# G32M3101 register map
File version: 1.0
CPU: CM0+ r0p1, little endian, MPU, no FPU, 2 interrupt priority bits
Registers are 32-bit, read-write, reset 0x0 unless marked. A register's access mark holds for its fields unless they carry their own. Offsets are from the block's base; [hi:lo] are bit positions; lines under a group give offsets from that group; {n}, {i} and the like mark numbered series.

## LPTMR — Low-power timer
Base 0x4000A000
0x00 CTRL — Control register
  [0] EN — Module enablement
0x04 PSC — Prescaler register
  [15:0] PSC — Prescaler divider
0x08 WUPV reset 0xFFFF — Reload register
  [15:0] WUPV — Awakening Value
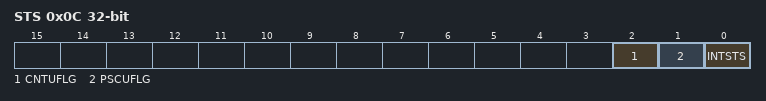
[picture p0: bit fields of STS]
0x0C STS access per field — Status register
  [2] CNTUFLG ro — Reload value update indication, automatically reset by hardware after update.
  [1] PSCUFLG ro — PS value update indicator, hardware automatically resets after update.
  [0] INTSTS rw — Status Register, read SR register clear.
0x10 CNT ro — Counter register
  [15:0] CNT — Counter Value

## SPI — Serial peripheral interface
Base 0x40003000
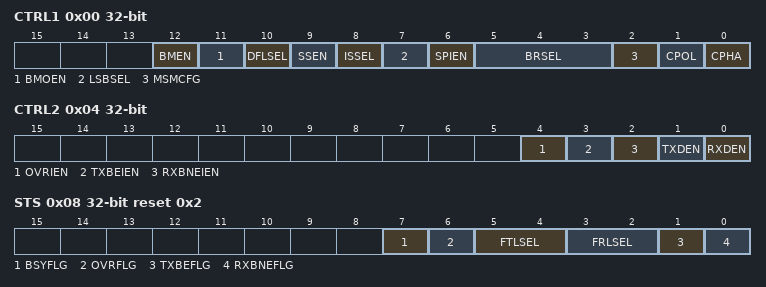
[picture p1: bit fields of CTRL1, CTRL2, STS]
0x00 CTRL1 — control register 1
  [12] BMEN — Bidirectional data mode enable
  [11] BMOEN — Output enable in bidirectional mode
  [10] DFLSEL — Receive only
  [9] SSEN — Software slave management
  [8] ISSEL — Internal slave select
  [7] LSBSEL — Frame format
  [6] SPIEN — SPI enable
  [5:3] BRSEL — Baud rate control
  [2] MSMCFG — Master selection
  [1] CPOL — Clock polarity
  [0] CPHA — Clock phase
0x04 CTRL2 — control register 2
  [4] OVRIEN — Overflow
  [3] TXBEIEN — Tx buffer empty interrupt enable
  [2] RXBNEIEN — SS output enable
  [1] TXDEN — Tx buffer DMA enable
  [0] RXDEN — Rx buffer DMA enable
0x08 STS ro reset 0x2 — status register
  [7] BSYFLG — Busy flag
  [6] OVRFLG — Overrun flag
  [5:4] FTLSEL — FTLVL
  [3:2] FRLSEL — FRLVL
  [1] TXBEFLG — Transmit buffer empty
  [0] RXBNEFLG — Receive buffer not empty
0x0C DATA
  [15:0] DATA

## UART0 — Universal asynchronous receiver transmitter
Base 0x40004000
Same registers: UART1 0x40005000
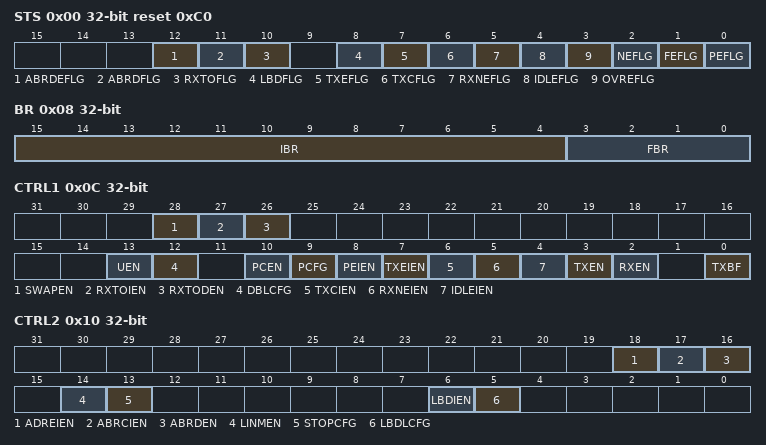
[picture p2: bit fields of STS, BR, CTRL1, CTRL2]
0x00 STS access per field reset 0xC0
  [12] ABRDEFLG rw — Auto Baud Rate Detection Error Flag
  [11] ABRDFLG rw — Auto Baud Rate Detection Flag
  [10] RXTOFLG rw — RX timeout flag
  [8] LBDFLG rw — LIN break detection flag
  [7] TXEFLG ro — Transmit data register empty
  [6] TXCFLG rw — Transmission complete
  [5] RXNEFLG rw — Read data register not empty
  [4] IDLEFLG ro — IDLE line detected
  [3] OVREFLG ro — Overrun error
  [2] NEFLG ro — Noise error flag
  [1] FEFLG ro — Framing error
  [0] PEFLG ro — Parity error
0x04 DATA
  [8:0] DATA — Data value
0x08 BR
  [15:4] IBR — IntegerwofwUARTwBaudwRatewDividerw factor
  [3:0] FBR — FractionwofwUARTwBaudwRatewDividerw factor
0x0C CTRL1
  [28] SWAPEN — Swap TX/RX Pins Function Enable
  [27] RXTOIEN — Receiver Timeout Interrupt Enable
  [26] RXTODEN — Receive Timeout Detection Function Enable
  [13] UEN — USART enable
  [12] DBLCFG — DatawBitswLengthwConfigure
  [10] PCEN — Parity control enable
  [9] PCFG — Parity selection
  [8] PEIEN — PE interrupt enable
  [7] TXEIEN — TXE interrupt enable
  [6] TXCIEN — Transmission complete interrupt enable
  [5] RXNEIEN — RXNE interrupt enable
  [4] IDLEIEN — IDLE interrupt enable
  [3] TXEN — Transmitter enable
  [2] RXEN — Receiver enable
  [0] TXBF — Send break
0x10 CTRL2
  [18] ADREIEN — Automaticwbaudwratewdetectionwerrorw interruptwenable
  [17] ABRCIEN — Automaticwbaudwratewcompletionwinterruptw enable
  [16] ABRDEN — AutowBaudwRatewDetectionwEnable
  [14] LINMEN — LIN mode enable
  [13] STOPCFG — STOP bits
  [6] LBDIEN — LIN break detection interrupt enable
  [5] LBDLCFG — LIN break detection length
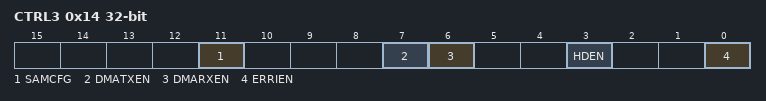
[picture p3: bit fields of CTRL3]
0x14 CTRL3
  [11] SAMCFG — Sample Method Configure
  [7] DMATXEN — DMA enable transmitter
  [6] DMARXEN — DMA enable receiver
  [3] HDEN — Half-duplex selection
  [0] ERRIEN — Error interrupt enable
0x1C RXTO
  [23:0] RXTO — Receiver Timeout Value Setup

## ADC — Analog-to-digital converter
Base 0x4000B000
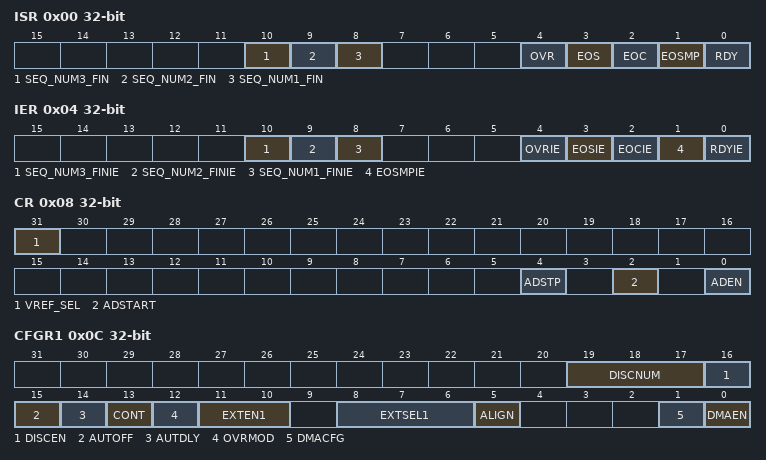
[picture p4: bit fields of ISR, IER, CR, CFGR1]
0x00 ISR — ADC interrupt and status register
  [10] SEQ_NUM3_FIN — NUM.3 of Sequential Section Sampling Finish
  [9] SEQ_NUM2_FIN — NUM.2 of Sequential Section Sampling Finish
  [8] SEQ_NUM1_FIN — NUM.1 of Sequential Section Sampling Finish
  [4] OVR — ADC group regular overrun flag
  [3] EOS — ADC group regular end of sequence conversions flag
  [2] EOC — ADC group regular end of unitary conversion flag
  [1] EOSMP — ADC group regular end of sampling flag
  [0] RDY — /
0x04 IER — ADC interrupt enable register
  [10] SEQ_NUM3_FINIE — NUM.3 of Sequential Section Sampling Finish interrupt
  [9] SEQ_NUM2_FINIE — NUM.2 of Sequential Section Sampling Finish interrupt
  [8] SEQ_NUM1_FINIE — NUM.1 of Sequential Section Sampling Finish interrupt
  [4] OVRIE — ADC group regular overrun interrupt
  [3] EOSIE — ADC group regular end of sequence conversions interrupt
  [2] EOCIE — ADC group regular end of unitary conversion interrupt
  [1] EOSMPIE — ADC group regular end of sampling interrupt
  [0] RDYIE — /
0x08 CR — ADC control register
  [31] VREF_SEL — ADC group injected conversion stop
  [4] ADSTP — ADC group regular conversion stop
  [2] ADSTART — ADC group regular conversion start
  [0] ADEN — ADC enable
0x0C CFGR1 — ADC configuration register 1
  [19:17] DISCNUM — ADC group regular sequencer discontinuous number of ranks
  [16] DISCEN — ADC group regular sequencer discontinuous mode
  [15] AUTOFF — ADC low power auto wait
  [14] AUTDLY — ADC low power auto wait
  [13] CONT — ADC group regular continuous conversion mode
  [12] OVRMOD — ADC group regular overrun configuration
  [11:10] EXTEN1 — ADC group regular external trigger polarity
  [8:6] EXTSEL1 — ADC group regular external trigger source
  [5] ALIGN — Data alignment
  [1] DMACFG — ADC DMA transfer configuration
  [0] DMAEN — ADC DMA transfer enable
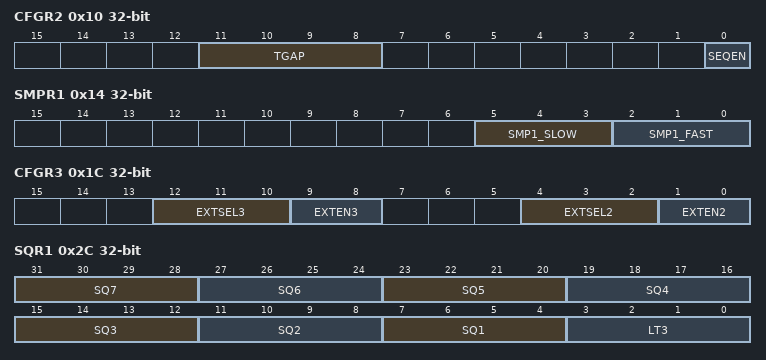
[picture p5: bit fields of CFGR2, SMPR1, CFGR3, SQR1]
0x10 CFGR2 — ADC configuration register 2
  [11:8] TGAP — Time of The Gap between Conversions in Sequential Section Configure
  [0] SEQEN — Sequential Section Sampling Enable
0x14 SMPR1 — ADC sampling time register 1
  [5:3] SMP1_SLOW — ADC channel 0 slow sampling time selection
  [2:0] SMP1_FAST — ADC channel 0 fast sampling time selection
0x1C CFGR3 — ADC configuration register 3
  [12:10] EXTSEL3 — External trigger selection for regular group
  [9:8] EXTEN3 — External trigger enable and polarity selection for regular channels
  [4:2] EXTSEL2 — External trigger selection for regular group
  [1:0] EXTEN2 — External trigger enable and polarity selection for regular channels
0x2C SQR1 — ADC group regular sequencer register 1
  [4n+3:4n] SQ{n} (n=1..7) — ADC group regular sequencer rank {n}
  [3:0] LT3 — ADC group regular sequencer scan length
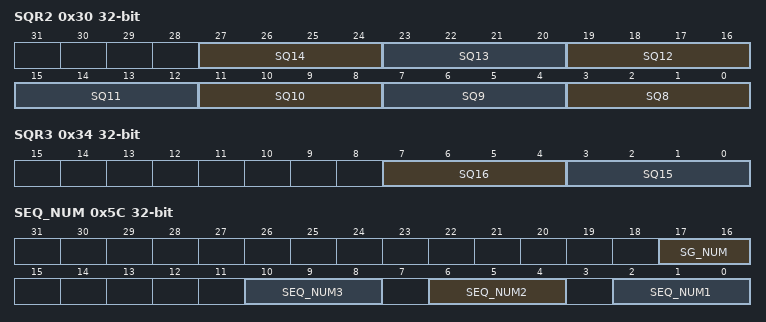
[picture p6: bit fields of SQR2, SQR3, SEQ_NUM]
0x30 SQR2 — ADC group regular sequencer register 2
  [4n-29:4n-32] SQ{n} (n=8..14) — ADC group regular sequencer rank {n}
0x34 SQR3 — ADC group regular sequencer register 3
  [7:4] SQ16 — ADC group regular sequencer rank 16
  [3:0] SQ15 — ADC group regular sequencer rank 15
0x38 DR ro — ADC group regular data register
  [15:0] RDATA — ADC group regular conversion data
{0x3C+4i} DATA{i} ro (i=0..5) — Segmented sampling result data {i}
  [15:0] RDATA{i} — /
0x54 DATA6 ro — Segmented sampling 6
  [15:0] RDATA6 — /
0x58 DATA7 ro — Segmented sampling result data 7
  [15:0] RDATA7 — /
0x5C SEQ_NUM — The Number of Sequencial Section
  [17:16] SG_NUM — The Number of Sequencial Section
  [10:8] SEQ_NUM3 — Section3 Transmission Time Setup
  [6:4] SEQ_NUM2 — Section2 Transmission Time Setup
  [2:0] SEQ_NUM1 — Section1 Transmission Time Setup
0x84 TMR — ADC timer mode register
  [0] CALC_BYPASS — /
